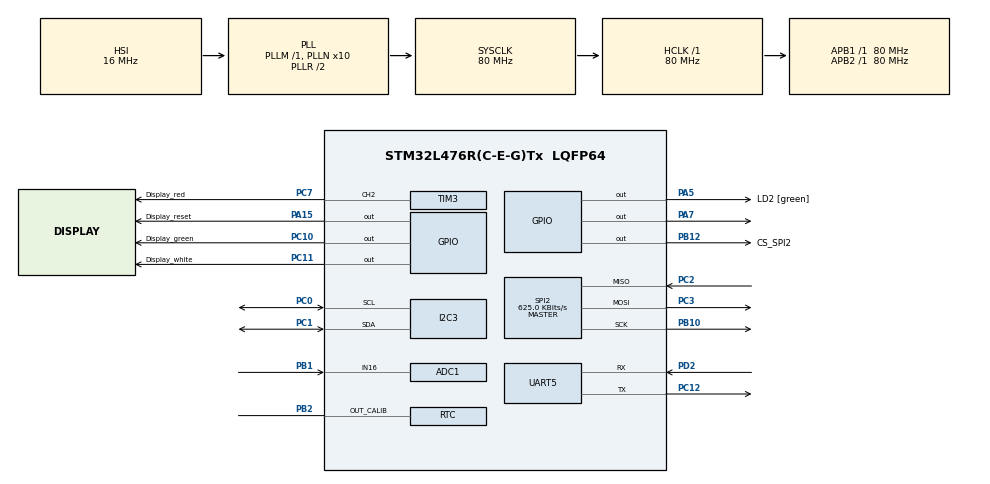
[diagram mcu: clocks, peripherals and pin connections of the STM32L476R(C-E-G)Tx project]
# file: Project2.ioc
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ADC1.Channel-0\#ChannelRegularConversion=ADC_CHANNEL_16
ADC1.NbrOfConversionFlag=1
ADC1.OffsetNumber-0\#ChannelRegularConversion=ADC_OFFSET_NONE
ADC1.Rank-0\#ChannelRegularConversion=1
ADC1.SamplingTime-0\#ChannelRegularConversion=ADC_SAMPLETIME_2CYCLES_5
ADC1.master=1
I2C3.Timing=0x10909CEC
Mcu.Family=STM32L4
Mcu.Name=STM32L476R(C-E-G)Tx
Mcu.Package=LQFP64
NVIC.PriorityGroup=NVIC_PRIORITYGROUP_4
NVIC.UART5_IRQn=true\:0\:0\:false\:false\:true\:true\:true
PA15\ (JTDI).GPIO_Label=Display_reset
PA15\ (JTDI).Signal=GPIO_Output
PA5.GPIO_Label=LD2 [green]
PA5.Signal=GPIO_Output
PA7.Signal=GPIO_Output
PB1.Signal=ADCx_IN16
PB10.Mode=Full_Duplex_Master
PB10.Signal=SPI2_SCK
PB12.GPIO_Label=CS_SPI2
PB12.Signal=GPIO_Output
PB2.Mode=Calibration_1Hz
PB2.Signal=RTC_OUT_CALIB
PC0.Mode=I2C
PC0.Signal=I2C3_SCL
PC1.Mode=I2C
PC1.Signal=I2C3_SDA
PC10.GPIO_Label=Display_green
PC10.Signal=GPIO_Output
PC11.GPIO_Label=Display_white
PC11.Signal=GPIO_Output
PC12.Mode=Asynchronous
PC12.Signal=UART5_TX
PC2.Mode=Full_Duplex_Master
PC2.Signal=SPI2_MISO
PC3.Mode=Full_Duplex_Master
PC3.Signal=SPI2_MOSI
PC7.GPIO_Label=Display_red 
PC7.Signal=S_TIM3_CH2
PD2.Mode=Asynchronous
PD2.Signal=UART5_RX
PH0-OSC_IN\ (PH0).GPIO_Label=RCC_OSC_IN
PH0-OSC_IN\ (PH0).Mode=HSE-External-Oscillator
PH0-OSC_IN\ (PH0).Signal=RCC_OSC_IN
PH1-OSC_OUT\ (PH1).GPIO_Label=RCC_OSC_OUT
PH1-OSC_OUT\ (PH1).Mode=HSE-External-Oscillator
PH1-OSC_OUT\ (PH1).Signal=RCC_OSC_OUT
ProjectManager.HeapSize=0x200
ProjectManager.StackSize=0x400
ProjectManager.TargetToolchain=STM32CubeIDE
RCC.ADCFreq_Value=64000000
RCC.AHBFreq_Value=80000000
RCC.APB1Freq_Value=80000000
RCC.APB1TimFreq_Value=80000000
RCC.APB2Freq_Value=80000000
RCC.APB2TimFreq_Value=80000000
RCC.CortexFreq_Value=80000000
RCC.HCLKFreq_Value=80000000
RCC.HSE_VALUE=8000000
RCC.HSI_VALUE=16000000
RCC.LSE_VALUE=32768
RCC.MSI_VALUE=4000000
RCC.PLLN=10
RCC.PLLSourceVirtual=RCC_PLLSOURCE_HSI
RCC.SYSCLKFreq_VALUE=80000000
RCC.SYSCLKSource=RCC_SYSCLKSOURCE_PLLCLK
RCC.USBFreq_Value=64000000
RCC.VCOOutputFreq_Value=160000000
RTC.AsynchPrediv=50-1
RTC.Hours=1
RTC.SynchPrediv=800-1
SH.ADCx_IN16.0=ADC1_IN16,IN16-Single-Ended
SH.S_TIM3_CH2.0=TIM3_CH2,PWM Generation2 CH2
SPI2.BaudRatePrescaler=SPI_BAUDRATEPRESCALER_128
SPI2.CLKPhase=SPI_PHASE_2EDGE
SPI2.CLKPolarity=SPI_POLARITY_HIGH
SPI2.CalculateBaudRate=625.0 KBits/s
SPI2.DataSize=SPI_DATASIZE_8BIT
SPI2.Direction=SPI_DIRECTION_2LINES
SPI2.FirstBit=SPI_FIRSTBIT_LSB
SPI2.Mode=SPI_MODE_MASTER
SPI2.VirtualType=VM_MASTER
TIM3.Channel-PWM\ Generation2\ CH2=TIM_CHANNEL_2
VP_RTC_VS_RTC_Activate.Mode=RTC_Enabled
VP_RTC_VS_RTC_Calendar.Mode=RTC_Calendar
board=custom

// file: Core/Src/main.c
/* USER CODE BEGIN Header */
/**
  ******************************************************************************
  * @file           : main.c
  * @brief          : Main program body
  ******************************************************************************
  * @attention
  *
  * <h2><center>&copy; Copyright (c) 2021 STMicroelectronics.
  * All rights reserved.</center></h2>
  *
  * This software component is licensed by ST under BSD 3-Clause license,
  * the "License"; You may not use this file except in compliance with the
  * License. You may obtain a copy of the License at:
  *                        opensource.org/licenses/BSD-3-Clause
  *
  ******************************************************************************
  */
/* USER CODE END Header */
#include "main.h"
#include "adc.h"
#include "i2c.h"
#include "rtc.h"
#include "spi.h"
#include "tim.h"
#include "usart.h"
#include "gpio.h"

/* USER CODE BEGIN Includes */
#include "string.h"
#include <stdio.h>
#include "test.h"
/* USER CODE END Includes */

/* USER CODE BEGIN PD */
#define RUN_TEST_PROGRAM // Undefine this to run main program
/* USER CODE END PD */

void SystemClock_Config(void);

int main(void)
{
  /* USER CODE BEGIN 1 */
   uint8_t Tecken;
   char *hello = "Programmet startar\n\r";

  /* USER CODE END 1 */

  /* MCU Configuration--------------------------------------------------------*/

  /* Reset of all peripherals, Initializes the Flash interface and the Systick. */
  HAL_Init();

  /* Configure the system clock */
  SystemClock_Config();

  /* Initialize all configured peripherals */
  MX_GPIO_Init();
  MX_UART5_Init();
  MX_ADC1_Init();
  MX_I2C3_Init();
  MX_RTC_Init();
  MX_SPI2_Init();
  MX_TIM3_Init();
  /* USER CODE BEGIN 2 */

  HAL_TIM_PWM_Start(&htim3, TIM_CHANNEL_2);
#ifdef RUN_TEST_PROGRAM
  test_program();
#endif

  HAL_UART_Transmit(&huart5, (uint8_t*)hello, strlen(hello), 5000);

  /* USER CODE END 2 */

  /* Infinite loop */
  /* USER CODE BEGIN WHILE */
  while (1)
  {

	  /*if (HAL_UART_Receive(&huart5, &Tecken, 1, 5000) != HAL_OK) {
	  Error_Handler(); }
	  if (HAL_UART_Transmit(&huart5, &Tecken, 1, 5000) != HAL_OK) {
	  Error_Handler(); }
	  */

	  HAL_UART_Receive(&huart5, &Tecken, 1, 5000);
	  HAL_UART_Transmit(&huart5, &Tecken, 1, 5000);

    /* USER CODE END WHILE */

  }
}

void SystemClock_Config(void)
{
  RCC_OscInitTypeDef RCC_OscInitStruct = {0};
  RCC_ClkInitTypeDef RCC_ClkInitStruct = {0};

  /** Configure the main internal regulator output voltage
  */
  if (HAL_PWREx_ControlVoltageScaling(PWR_REGULATOR_VOLTAGE_SCALE1) != HAL_OK)
  {
    Error_Handler();
  }
  /** Initializes the RCC Oscillators according to the specified parameters
  * in the RCC_OscInitTypeDef structure.
  */
  RCC_OscInitStruct.OscillatorType = RCC_OSCILLATORTYPE_HSI|RCC_OSCILLATORTYPE_LSI;
  RCC_OscInitStruct.HSIState = RCC_HSI_ON;
  RCC_OscInitStruct.HSICalibrationValue = RCC_HSICALIBRATION_DEFAULT;
  RCC_OscInitStruct.LSIState = RCC_LSI_ON;
  RCC_OscInitStruct.PLL.PLLState = RCC_PLL_ON;
  RCC_OscInitStruct.PLL.PLLSource = RCC_PLLSOURCE_HSI;
  RCC_OscInitStruct.PLL.PLLM = 1;
  RCC_OscInitStruct.PLL.PLLN = 10;
  RCC_OscInitStruct.PLL.PLLP = RCC_PLLP_DIV7;
  RCC_OscInitStruct.PLL.PLLQ = RCC_PLLQ_DIV2;
  RCC_OscInitStruct.PLL.PLLR = RCC_PLLR_DIV2;
  if (HAL_RCC_OscConfig(&RCC_OscInitStruct) != HAL_OK)
  {
    Error_Handler();
  }
  /** Initializes the CPU, AHB and APB buses clocks
  */
  RCC_ClkInitStruct.ClockType = RCC_CLOCKTYPE_HCLK|RCC_CLOCKTYPE_SYSCLK
                              |RCC_CLOCKTYPE_PCLK1|RCC_CLOCKTYPE_PCLK2;
  RCC_ClkInitStruct.SYSCLKSource = RCC_SYSCLKSOURCE_PLLCLK;
  RCC_ClkInitStruct.AHBCLKDivider = RCC_SYSCLK_DIV1;
  RCC_ClkInitStruct.APB1CLKDivider = RCC_HCLK_DIV1;
  RCC_ClkInitStruct.APB2CLKDivider = RCC_HCLK_DIV1;

  if (HAL_RCC_ClockConfig(&RCC_ClkInitStruct, FLASH_LATENCY_4) != HAL_OK)
  {
    Error_Handler();
  }
}

void Error_Handler(void)
{
  /* USER CODE BEGIN Error_Handler_Debug */
  //HAL_GPIO_WritePin(LED2_GPIO_Port, LED2_Pin, GPIO_PIN_SET);
  /* User can add his own implementation to report the HAL error return state */
  __disable_irq();
  while (1)
  {
  }
  /* USER CODE END Error_Handler_Debug */
}

/************************ (C) COPYRIGHT STMicroelectronics *****END OF FILE****/
